# HC32M458 register map
File version: 1.0
CPU: CM4 r0p1, little endian, MPU, FPU, 4 interrupt priority bits
Registers are 16-bit, read-write, reset 0x0 unless marked. A register's access mark holds for its fields unless they carry their own. Offsets are from the block's base; [hi:lo] are bit positions; {n}, {i} and the like mark numbered series.

## I2C
Base 0x4003B400
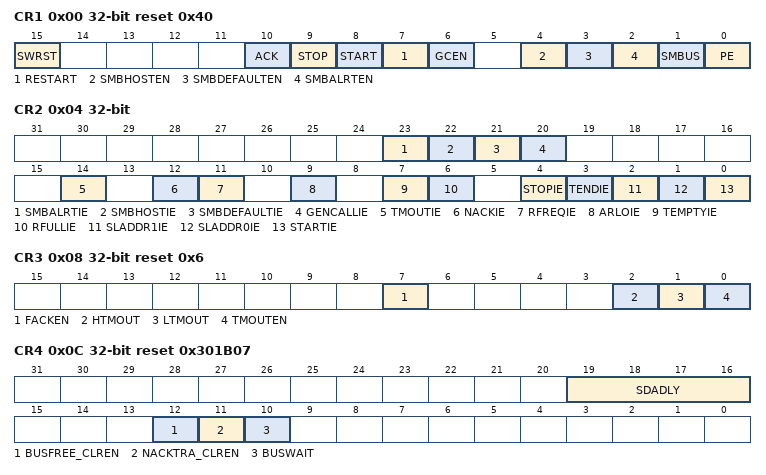
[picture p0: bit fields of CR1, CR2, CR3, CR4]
0x00 CR1 32-bit reset 0x40
  [15] SWRST, [10] ACK, [9] STOP, [8] START, [7] RESTART, [6] GCEN, [4] SMBHOSTEN, [3] SMBDEFAULTEN, [2] SMBALRTEN, [1] SMBUS, [0] PE
0x04 CR2 32-bit
  [23] SMBALRTIE, [22] SMBHOSTIE, [21] SMBDEFAULTIE, [20] GENCALLIE, [14] TMOUTIE, [12] NACKIE, [11] RFREQIE, [9] ARLOIE, [7] TEMPTYIE, [6] RFULLIE, [4] STOPIE, [3] TENDIE, [2] SLADDR1IE, [1] SLADDR0IE, [0] STARTIE
0x08 CR3 32-bit reset 0x6
  [7] FACKEN, [2] HTMOUT, [1] LTMOUT, [0] TMOUTEN
0x0C CR4 32-bit reset 0x301B07
  [19:16] SDADLY, [12] BUSFREE_CLREN, [11] NACKTRA_CLREN, [10] BUSWAIT
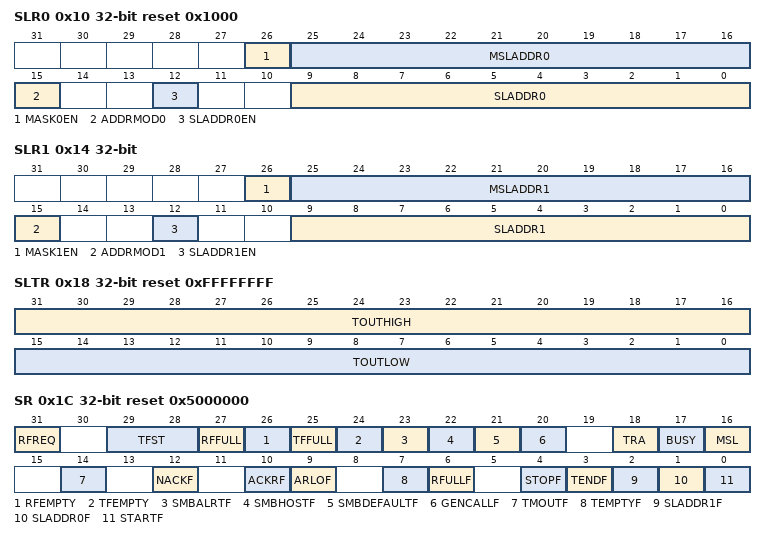
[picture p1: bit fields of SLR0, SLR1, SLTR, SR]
0x10 SLR0 32-bit reset 0x1000
  [26] MASK0EN, [25:16] MSLADDR0, [15] ADDRMOD0, [12] SLADDR0EN, [9:0] SLADDR0
0x14 SLR1 32-bit
  [26] MASK1EN, [25:16] MSLADDR1, [15] ADDRMOD1, [12] SLADDR1EN, [9:0] SLADDR1
0x18 SLTR 32-bit reset 0xFFFFFFFF
  [31:16] TOUTHIGH, [15:0] TOUTLOW
0x1C SR 32-bit reset 0x5000000
  [31] RFREQ ro, [29:28] TFST ro, [27] RFFULL ro, [26] RFEMPTY ro, [25] TFFULL ro, [24] TFEMPTY ro, [23] SMBALRTF ro, [22] SMBHOSTF ro, [21] SMBDEFAULTF ro, [20] GENCALLF ro, [18] TRA, [17] BUSY ro, [16] MSL, [14] TMOUTF ro, [12] NACKF ro, [10] ACKRF ro, [9] ARLOF ro, [7] TEMPTYF ro, [6] RFULLF ro, [4] STOPF ro, [3] TENDF ro, [2] SLADDR1F ro, [1] SLADDR0F ro, [0] STARTF ro
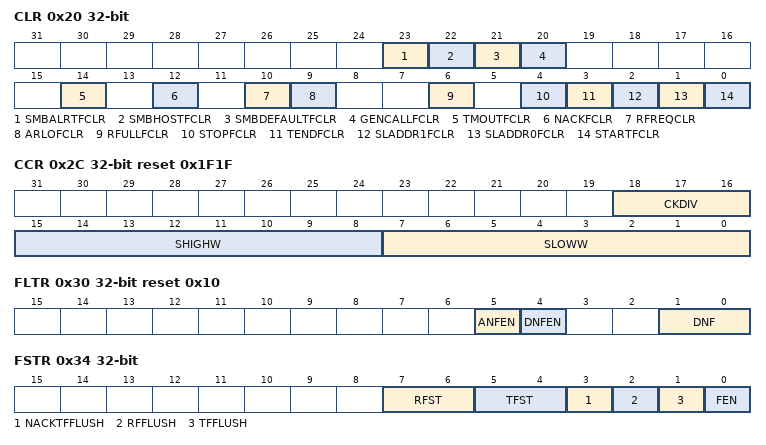
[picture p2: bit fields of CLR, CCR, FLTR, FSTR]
0x20 CLR 32-bit wo
  [23] SMBALRTFCLR, [22] SMBHOSTFCLR, [21] SMBDEFAULTFCLR, [20] GENCALLFCLR, [14] TMOUTFCLR, [12] NACKFCLR, [10] RFREQCLR, [9] ARLOFCLR, [6] RFULLFCLR, [4] STOPFCLR, [3] TENDFCLR, [2] SLADDR1FCLR, [1] SLADDR0FCLR, [0] STARTFCLR
0x24 DTR 8-bit reset 0xFF
0x28 DRR 8-bit ro
0x2C CCR 32-bit reset 0x1F1F
  [18:16] CKDIV, [15:8] SHIGHW, [7:0] SLOWW
0x30 FLTR 32-bit reset 0x10
  [5] ANFEN, [4] DNFEN, [1:0] DNF
0x34 FSTR 32-bit
  [7:6] RFST, [5:4] TFST, [3] NACKTFFLUSH, [2] RFFLUSH, [1] TFFLUSH, [0] FEN
0x38 SLVADDR 32-bit
  [9:0] SLVADRR

## ICG
Base 0x00080000
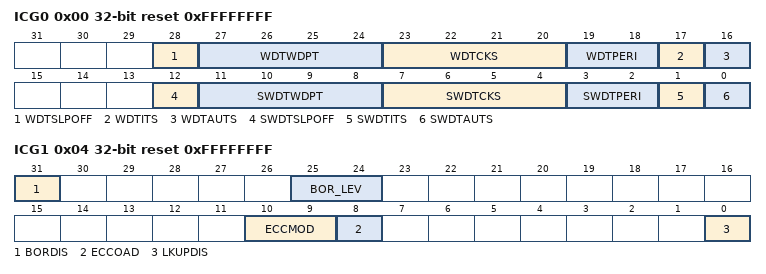
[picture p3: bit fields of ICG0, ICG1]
0x00 ICG0 32-bit ro reset 0xFFFFFFFF
  [28] WDTSLPOFF, [27:24] WDTWDPT, [23:20] WDTCKS, [19:18] WDTPERI, [17] WDTITS, [16] WDTAUTS, [12] SWDTSLPOFF, [11:8] SWDTWDPT, [7:4] SWDTCKS, [3:2] SWDTPERI, [1] SWDTITS, [0] SWDTAUTS
0x04 ICG1 32-bit ro reset 0xFFFFFFFF
  [31] BORDIS, [25:24] BOR_LEV, [10:9] ECCMOD, [8] ECCOAD, [0] LKUPDIS
0x08 ICG2 32-bit ro reset 0xFFFFFFFF
0x10 ICG4 32-bit ro reset 0xFFFFFFFF

## INTC
Base 0x40051000
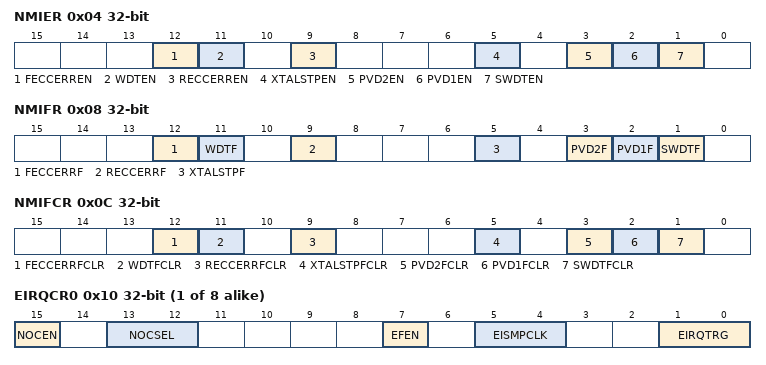
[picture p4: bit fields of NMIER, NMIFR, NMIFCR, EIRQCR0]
0x04 NMIER 32-bit
  [12] FECCERREN, [11] WDTEN, [9] RECCERREN, [5] XTALSTPEN, [3] PVD2EN, [2] PVD1EN, [1] SWDTEN
0x08 NMIFR 32-bit
  [12] FECCERRF, [11] WDTF, [9] RECCERRF, [5] XTALSTPF, [3] PVD2F, [2] PVD1F, [1] SWDTF
0x0C NMIFCR 32-bit
  [12] FECCERRFCLR, [11] WDTFCLR, [9] RECCERRFCLR, [5] XTALSTPFCLR, [3] PVD2FCLR, [2] PVD1FCLR, [1] SWDTFCLR
{0x10+4i} EIRQCR{i} 32-bit (i=0..7)
  [15] NOCEN, [13:12] NOCSEL, [7] EFEN, [5:4] EISMPCLK, [1:0] EIRQTRG
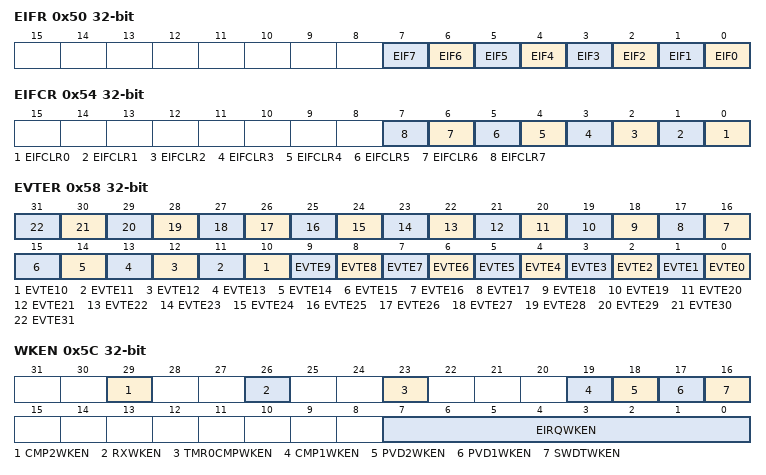
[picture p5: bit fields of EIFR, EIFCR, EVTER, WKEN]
0x50 EIFR 32-bit
  [n] EIF{n} (n=0..7)
0x54 EIFCR 32-bit
  [n] EIFCLR{n} (n=0..7)
0x58 EVTER 32-bit
  [n] EVTE{n} (n=0..31)
0x5C WKEN 32-bit
  [29] CMP2WKEN, [26] RXWKEN, [23] TMR0CMPWKEN, [19] CMP1WKEN, [18] PVD2WKEN, [17] PVD1WKEN, [16] SWDTWKEN, [7:0] EIRQWKEN
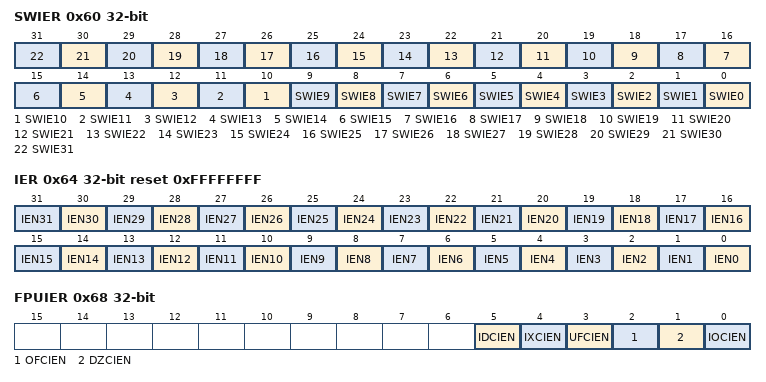
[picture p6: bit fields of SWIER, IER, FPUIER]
0x60 SWIER 32-bit
  [n] SWIE{n} (n=0..31)
0x64 IER 32-bit reset 0xFFFFFFFF
  [n] IEN{n} (n=0..31)
0x68 FPUIER 32-bit
  [5] IDCIEN, [4] IXCIEN, [3] UFCIEN, [2] OFCIEN, [1] DZCIEN, [0] IOCIEN

## MAU
Base 0x40054800
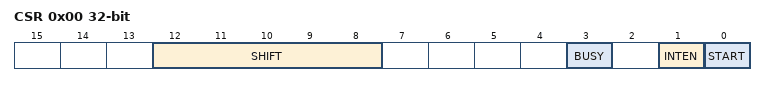
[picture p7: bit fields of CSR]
0x00 CSR 32-bit
  [12:8] SHIFT, [3] BUSY, [1] INTEN, [0] START
0x04 DTR0 32-bit
0x0C RTR0 32-bit
0x1C DTR1 32-bit
  [11:0] SIN_DIN
0x20 RTR1 32-bit
  [15:0] SIN_DOUT
0x24 ATAN_DIN 32-bit
  [11:0] ATAN_DIN
0x28 ATAN_DOUT 32-bit
  [15:0] ATAN_DOUT

## PERIC
Base 0x40055400
0x0C SMC_ENAR 32-bit
  [1] SMCEN
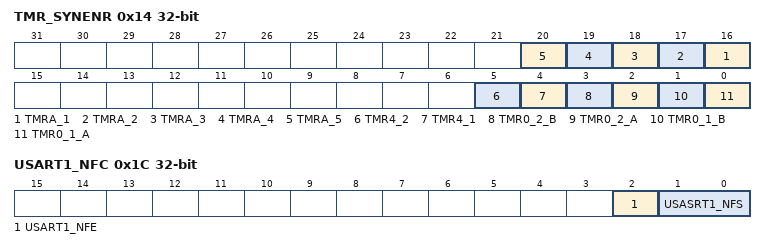
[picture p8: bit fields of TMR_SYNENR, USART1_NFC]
0x14 TMR_SYNENR 32-bit
  [n+15] TMRA_{n} (n=1..5), [5] TMR4_2, [4] TMR4_1, [3] TMR0_2_B, [2] TMR0_2_A, [1] TMR0_1_B, [0] TMR0_1_A
0x1C USART1_NFC 32-bit
  [2] USART1_NFE, [1:0] USASRT1_NFS
